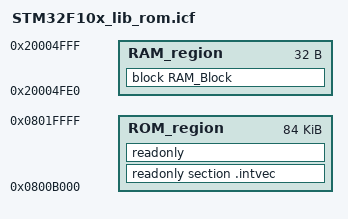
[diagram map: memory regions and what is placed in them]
/*###ICF### Section handled by ICF editor, don't touch! ****/
/*-Editor annotation file-*/
/* IcfEditorFile="$TOOLKIT_DIR$\config\ide\IcfEditor\a_v1_0.xml" */
/*-Specials-*/
define symbol __ICFEDIT_intvec_start__ = 0x08003000;
/*-Memory Regions-*/
define symbol __ICFEDIT_region_ROM_start__ = 0x0800B000;
define symbol __ICFEDIT_region_ROM_end__   = 0x0801FFFF;
define symbol __ICFEDIT_region_RAM_start__ = 0x20005000 - 0x0020;
define symbol __ICFEDIT_region_RAM_end__   = 0x20004FFF;
/*-Sizes-*/
define symbol __ICFEDIT_size_cstack__ = 0x0;
define symbol __ICFEDIT_size_heap__   = 0x200;
/**** End of ICF editor section. ###ICF###*/


define memory mem with size = 4G;
define region ROM_region   = mem:[from __ICFEDIT_region_ROM_start__   to __ICFEDIT_region_ROM_end__];
define region RAM_region   = mem:[from __ICFEDIT_region_RAM_start__   to __ICFEDIT_region_RAM_end__];

define block CSTACK    with alignment = 4, size = __ICFEDIT_size_cstack__   { };
//place at address mem:( __ICFEDIT_region_RAM_end__ + 1 ) { block CSTACK };

define block HEAP      with alignment = 4, size = __ICFEDIT_size_heap__     { };

initialize by copy { readwrite };
do not initialize  { section .noinit };

define block RAM_Block with fixed order { block CSTACK, rw, block HEAP, section .BottomOfSram };

place in ROM_region   { readonly section .intvec, readonly };
place in RAM_region   { block RAM_Block };
